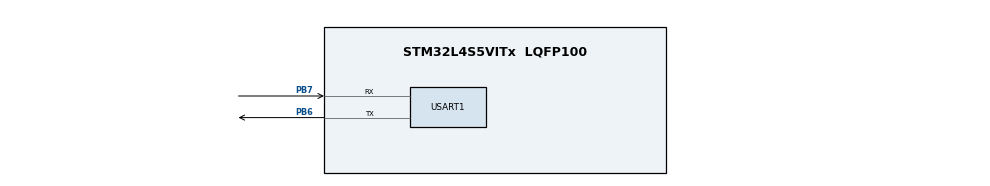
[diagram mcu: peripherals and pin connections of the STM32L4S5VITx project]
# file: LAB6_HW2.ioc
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ADC1.Channel-0\#ChannelRegularConversion=ADC_CHANNEL_TEMPSENSOR
ADC1.ClockPrescaler=ADC_CLOCK_SYNC_PCLK_DIV4
ADC1.DMAContinuousRequests=ENABLE
ADC1.ExternalTrigConv=ADC_EXTERNALTRIG_T1_TRGO
ADC1.NbrOfConversionFlag=1
ADC1.OffsetNumber-0\#ChannelRegularConversion=ADC_OFFSET_NONE
ADC1.Rank-0\#ChannelRegularConversion=1
ADC1.SamplingTime-0\#ChannelRegularConversion=ADC_SAMPLETIME_247CYCLES_5
ADC1.master=1
Dma.ADC1.0.Direction=DMA_PERIPH_TO_MEMORY
Dma.ADC1.0.EventEnable=DISABLE
Dma.ADC1.0.Instance=DMA1_Channel1
Dma.ADC1.0.MemDataAlignment=DMA_MDATAALIGN_HALFWORD
Dma.ADC1.0.MemInc=DMA_MINC_ENABLE
Dma.ADC1.0.Mode=DMA_CIRCULAR
Dma.ADC1.0.PeriphDataAlignment=DMA_PDATAALIGN_HALFWORD
Dma.ADC1.0.PeriphInc=DMA_PINC_DISABLE
Dma.ADC1.0.Polarity=HAL_DMAMUX_REQUEST_GEN_RISING
Dma.ADC1.0.Priority=DMA_PRIORITY_HIGH
Dma.ADC1.0.RequestNumber=1
Dma.ADC1.0.SignalID=NONE
Dma.ADC1.0.SyncEnable=DISABLE
Dma.ADC1.0.SyncPolarity=HAL_DMAMUX_SYNC_NO_EVENT
Dma.ADC1.0.SyncRequestNumber=1
Dma.ADC1.0.SyncSignalID=NONE
Dma.Request0=ADC1
Mcu.Family=STM32L4
Mcu.Name=STM32L4S5VITx
Mcu.Package=LQFP100
NVIC.ADC1_IRQn=true\:0\:0\:false\:false\:true\:true\:true\:true
NVIC.DMA1_Channel1_IRQn=true\:0\:0\:false\:false\:true\:false\:true\:true
NVIC.PriorityGroup=NVIC_PRIORITYGROUP_4
PB6.Mode=Asynchronous
PB6.Signal=USART1_TX
PB7.Mode=Asynchronous
PB7.Signal=USART1_RX
PH0-OSC_IN\ (PH0).Mode=HSE-External-Oscillator
PH0-OSC_IN\ (PH0).Signal=RCC_OSC_IN
PH1-OSC_OUT\ (PH1).Mode=HSE-External-Oscillator
PH1-OSC_OUT\ (PH1).Signal=RCC_OSC_OUT
ProjectManager.HeapSize=0x200
ProjectManager.StackSize=0x400
ProjectManager.TargetToolchain=STM32CubeIDE
RCC.HSE_VALUE=8000000
RCC.HSI48_VALUE=48000000
RCC.HSI_VALUE=16000000
RCC.LSE_VALUE=32768
RCC.MSI_VALUE=4000000
RCC.VCOOutputFreq_Value=32000000
TIM1.Period=99
TIM1.Prescaler=3999
TIM1.TIM_MasterOutputTrigger=TIM_TRGO_UPDATE
TIM1.TIM_MasterSlaveMode=TIM_MASTERSLAVEMODE_DISABLE
USART1.VirtualMode-Asynchronous=VM_ASYNC
VP_ADC1_TempSens_Input.Mode=IN-TempSens
VP_TIM1_VS_ClockSourceINT.Mode=Internal
board=custom

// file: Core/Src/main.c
/* USER CODE BEGIN Header */
/**
  ******************************************************************************
  * @file           : main.c
  * @brief          : Main program body
  ******************************************************************************
  * @attention
  *
  * Copyright (c) 2025 STMicroelectronics.
  * All rights reserved.
  *
  * This software is licensed under terms that can be found in the LICENSE file
  * in the root directory of this software component.
  * If no LICENSE file comes with this software, it is provided AS-IS.
  *
  ******************************************************************************
  */
/* USER CODE END Header */
#include "main.h"

/* USER CODE BEGIN Includes */
#include<stdio.h>
/* USER CODE END Includes */

ADC_HandleTypeDef hadc1;
DMA_HandleTypeDef hdma_adc1;

TIM_HandleTypeDef htim1;

UART_HandleTypeDef huart1;

void SystemClock_Config(void);
static void MX_GPIO_Init(void);
static void MX_DMA_Init(void);
static void MX_TIM1_Init(void);
static void MX_USART1_UART_Init(void);
static void MX_ADC1_Init(void);
/* USER CODE BEGIN PFP */
#define SAMPLE_BUFFER_SIZE  256
uint16_t sample_buffer[SAMPLE_BUFFER_SIZE];
/* USER CODE END PFP */

/* USER CODE BEGIN 0 */
int __io_putchar(int ch)
{
	uint8_t c = ch;
	HAL_UART_Transmit(&huart1, &c, 1, HAL_MAX_DELAY);
	return ch;
}

//void ADC1_DMA1CH1_init()
//{
//    __HAL_RCC_DMA1_CLK_ENABLE();
//
//    hdma_adc1.Instance = DMA1_Channel1;
//    hdma_adc1.Init.Direction = DMA_PERIPH_TO_MEMORY;
//    hdma_adc1.Init.PeriphInc = DMA_PINC_DISABLE;
//    hdma_adc1.Init.MemInc = DMA_MINC_ENABLE;
//    hdma_adc1.Init.PeriphDataAlignment = DMA_PDATAALIGN_HALFWORD;
//    hdma_adc1.Init.MemDataAlignment = DMA_MDATAALIGN_HALFWORD;
//    hdma_adc1.Init.Mode = DMA_CIRCULAR;
//    hdma_adc1.Init.Priority = DMA_PRIORITY_HIGH;
//
//    if (HAL_DMA_Init(&hdma_adc1) != HAL_OK)
//    {
//        Error_Handler();
//    }
//
//    __HAL_LINKDMA(&hadc1, DMA_Handle, hdma_adc1);
//
//    MX_ADC1_Init();
//
//    // 不需要自己設 vector，HAL 已處理
////     NVIC_SetVector(DMA1_Channel1_IRQn, (uint32_t)&DMA1_Channel1_IRQHandler);
//
//    HAL_NVIC_SetPriority(DMA1_Channel1_IRQn, 6, 0);
//    HAL_NVIC_EnableIRQ(DMA1_Channel1_IRQn);
//}

void ADC1_DMA1CH1_init(void)
{
    __HAL_RCC_DMAMUX1_CLK_ENABLE();      // ⚠️ L4S5 一定要開 DMAMUX1 clock
    __HAL_RCC_DMA1_CLK_ENABLE();

    MX_ADC1_Init();                      // ⚠️ 先建好 hadc1.Instance

    hdma_adc1.Instance                 = DMA1_Channel1;
    hdma_adc1.Init.Request             = DMA_REQUEST_ADC1;   // ⚠️ 指定 ADC1 作為請求源
    hdma_adc1.Init.Direction           = DMA_PERIPH_TO_MEMORY;
    hdma_adc1.Init.PeriphInc           = DMA_PINC_DISABLE;
    hdma_adc1.Init.MemInc              = DMA_MINC_ENABLE;
    hdma_adc1.Init.PeriphDataAlignment = DMA_PDATAALIGN_HALFWORD;
    hdma_adc1.Init.MemDataAlignment    = DMA_MDATAALIGN_HALFWORD;
    hdma_adc1.Init.Mode                = DMA_CIRCULAR;
    hdma_adc1.Init.Priority            = DMA_PRIORITY_HIGH;

    if (HAL_DMA_Init(&hdma_adc1) != HAL_OK) Error_Handler();

    __HAL_LINKDMA(&hadc1, DMA_Handle, hdma_adc1); // ⚠️ 放在 MX_ADC1_Init() 之後

    HAL_NVIC_SetPriority(DMA1_Channel1_IRQn, 6, 0);
    HAL_NVIC_EnableIRQ(DMA1_Channel1_IRQn);
}

void HAL_ADC_ConvCpltCallback(ADC_HandleTypeDef *hadc)
{
	//to do: inform RTOS task to print out sensor data
	int i;
	for(i=SAMPLE_BUFFER_SIZE/2;i <SAMPLE_BUFFER_SIZE;++i)
		printf("%d\n",sample_buffer[i]);
}

void HAL_ADC_ConvHalfCpltCallback(ADC_HandleTypeDef *hadc)
{
    	//to do: inform RTOS task to print out sensor data
	int i;
	for(i=0;i <SAMPLE_BUFFER_SIZE/2;++i)
		printf("%d\n",sample_buffer[i]);
}

//void DMA1_Channel1_IRQHandler(void)
//{
//    SET_BIT(hadc1.Instance->CFGR, ADC_CFGR_DMACFG);
//    HAL_DMA_IRQHandler(&hdma_adc1);
//}

/* USER CODE END 0 */

int main(void)
{

  /* MCU Configuration--------------------------------------------------------*/

  /* Reset of all peripherals, Initializes the Flash interface and the Systick. */
  HAL_Init();

  /* Configure the system clock */
  SystemClock_Config();

  /* Initialize all configured peripherals */
  MX_GPIO_Init();
//  MX_DMA_Init();
  MX_TIM1_Init();
  MX_USART1_UART_Init();
//  MX_ADC1_Init();
  /* USER CODE BEGIN 2 */
  ADC1_DMA1CH1_init();
  HAL_ADC_Start_DMA(&hadc1, (uint32_t *)&sample_buffer[0], SAMPLE_BUFFER_SIZE);
  HAL_TIM_Base_Start_IT(&htim1);
  /* USER CODE END 2 */

  /* Infinite loop */
  while (1)
  {

  }
}

void SystemClock_Config(void)
{
  RCC_OscInitTypeDef RCC_OscInitStruct = {0};
  RCC_ClkInitTypeDef RCC_ClkInitStruct = {0};

  /** Configure the main internal regulator output voltage
  */
  if (HAL_PWREx_ControlVoltageScaling(PWR_REGULATOR_VOLTAGE_SCALE1) != HAL_OK)
  {
    Error_Handler();
  }

  /** Initializes the RCC Oscillators according to the specified parameters
  * in the RCC_OscInitTypeDef structure.
  */
  RCC_OscInitStruct.OscillatorType = RCC_OSCILLATORTYPE_MSI;
  RCC_OscInitStruct.MSIState = RCC_MSI_ON;
  RCC_OscInitStruct.MSICalibrationValue = 0;
  RCC_OscInitStruct.MSIClockRange = RCC_MSIRANGE_6;
  RCC_OscInitStruct.PLL.PLLState = RCC_PLL_NONE;
  if (HAL_RCC_OscConfig(&RCC_OscInitStruct) != HAL_OK)
  {
    Error_Handler();
  }

  /** Initializes the CPU, AHB and APB buses clocks
  */
  RCC_ClkInitStruct.ClockType = RCC_CLOCKTYPE_HCLK|RCC_CLOCKTYPE_SYSCLK
                              |RCC_CLOCKTYPE_PCLK1|RCC_CLOCKTYPE_PCLK2;
  RCC_ClkInitStruct.SYSCLKSource = RCC_SYSCLKSOURCE_MSI;
  RCC_ClkInitStruct.AHBCLKDivider = RCC_SYSCLK_DIV1;
  RCC_ClkInitStruct.APB1CLKDivider = RCC_HCLK_DIV1;
  RCC_ClkInitStruct.APB2CLKDivider = RCC_HCLK_DIV1;

  if (HAL_RCC_ClockConfig(&RCC_ClkInitStruct, FLASH_LATENCY_0) != HAL_OK)
  {
    Error_Handler();
  }
}

static void MX_ADC1_Init(void)
{

  ADC_ChannelConfTypeDef sConfig = {0};

  /** Common config
  */
  hadc1.Instance = ADC1;
  hadc1.Init.ClockPrescaler = ADC_CLOCK_SYNC_PCLK_DIV4;
  hadc1.Init.Resolution = ADC_RESOLUTION_12B;
  hadc1.Init.DataAlign = ADC_DATAALIGN_RIGHT;
  hadc1.Init.ScanConvMode = ADC_SCAN_DISABLE;
  hadc1.Init.EOCSelection = ADC_EOC_SINGLE_CONV;
  hadc1.Init.LowPowerAutoWait = DISABLE;
  hadc1.Init.ContinuousConvMode = DISABLE;
  hadc1.Init.NbrOfConversion = 1;
  hadc1.Init.DiscontinuousConvMode = DISABLE;
  hadc1.Init.ExternalTrigConv = ADC_EXTERNALTRIG_T1_TRGO;
  hadc1.Init.ExternalTrigConvEdge = ADC_EXTERNALTRIGCONVEDGE_RISING;
  hadc1.Init.DMAContinuousRequests = ENABLE;
  hadc1.Init.Overrun = ADC_OVR_DATA_PRESERVED;
  hadc1.Init.OversamplingMode = DISABLE;
  if (HAL_ADC_Init(&hadc1) != HAL_OK)
  {
    Error_Handler();
  }

  /** Configure Regular Channel
  */
  sConfig.Channel = ADC_CHANNEL_TEMPSENSOR;
  sConfig.Rank = ADC_REGULAR_RANK_1;
  sConfig.SamplingTime = ADC_SAMPLETIME_247CYCLES_5;
  sConfig.SingleDiff = ADC_SINGLE_ENDED;
  sConfig.OffsetNumber = ADC_OFFSET_NONE;
  sConfig.Offset = 0;
  if (HAL_ADC_ConfigChannel(&hadc1, &sConfig) != HAL_OK)
  {
    Error_Handler();
  }

}

static void MX_TIM1_Init(void)
{

  TIM_ClockConfigTypeDef sClockSourceConfig = {0};
  TIM_MasterConfigTypeDef sMasterConfig = {0};

  htim1.Instance = TIM1;
  htim1.Init.Prescaler = 3999;
  htim1.Init.CounterMode = TIM_COUNTERMODE_UP;
  htim1.Init.Period = 99;
  htim1.Init.ClockDivision = TIM_CLOCKDIVISION_DIV1;
  htim1.Init.RepetitionCounter = 0;
  htim1.Init.AutoReloadPreload = TIM_AUTORELOAD_PRELOAD_DISABLE;
  if (HAL_TIM_Base_Init(&htim1) != HAL_OK)
  {
    Error_Handler();
  }
  sClockSourceConfig.ClockSource = TIM_CLOCKSOURCE_INTERNAL;
  if (HAL_TIM_ConfigClockSource(&htim1, &sClockSourceConfig) != HAL_OK)
  {
    Error_Handler();
  }
  sMasterConfig.MasterOutputTrigger = TIM_TRGO_UPDATE;
  sMasterConfig.MasterOutputTrigger2 = TIM_TRGO2_RESET;
  sMasterConfig.MasterSlaveMode = TIM_MASTERSLAVEMODE_DISABLE;
  if (HAL_TIMEx_MasterConfigSynchronization(&htim1, &sMasterConfig) != HAL_OK)
  {
    Error_Handler();
  }

}

static void MX_USART1_UART_Init(void)
{

  huart1.Instance = USART1;
  huart1.Init.BaudRate = 115200;
  huart1.Init.WordLength = UART_WORDLENGTH_8B;
  huart1.Init.StopBits = UART_STOPBITS_1;
  huart1.Init.Parity = UART_PARITY_NONE;
  huart1.Init.Mode = UART_MODE_TX_RX;
  huart1.Init.HwFlowCtl = UART_HWCONTROL_NONE;
  huart1.Init.OverSampling = UART_OVERSAMPLING_16;
  huart1.Init.OneBitSampling = UART_ONE_BIT_SAMPLE_DISABLE;
  huart1.Init.ClockPrescaler = UART_PRESCALER_DIV1;
  huart1.AdvancedInit.AdvFeatureInit = UART_ADVFEATURE_NO_INIT;
  if (HAL_UART_Init(&huart1) != HAL_OK)
  {
    Error_Handler();
  }
  if (HAL_UARTEx_SetTxFifoThreshold(&huart1, UART_TXFIFO_THRESHOLD_1_8) != HAL_OK)
  {
    Error_Handler();
  }
  if (HAL_UARTEx_SetRxFifoThreshold(&huart1, UART_RXFIFO_THRESHOLD_1_8) != HAL_OK)
  {
    Error_Handler();
  }
  if (HAL_UARTEx_DisableFifoMode(&huart1) != HAL_OK)
  {
    Error_Handler();
  }

}

static void MX_DMA_Init(void)
{

  /* DMA controller clock enable */
  __HAL_RCC_DMAMUX1_CLK_ENABLE();
  __HAL_RCC_DMA1_CLK_ENABLE();

  /* DMA interrupt init */
  /* DMA1_Channel1_IRQn interrupt configuration */
  HAL_NVIC_SetPriority(DMA1_Channel1_IRQn, 0, 0);
  HAL_NVIC_EnableIRQ(DMA1_Channel1_IRQn);

}

static void MX_GPIO_Init(void)
{

  /* GPIO Ports Clock Enable */
  __HAL_RCC_GPIOH_CLK_ENABLE();
  __HAL_RCC_GPIOB_CLK_ENABLE();

}

void Error_Handler(void)
{
  __disable_irq();
  while (1)
  {
  }
}
